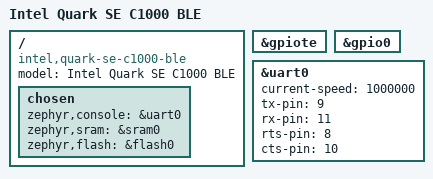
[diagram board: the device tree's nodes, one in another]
/*
 * Copyright (c) 2017 Linaro Limited
 *
 * SPDX-License-Identifier: Apache-2.0
 */

/dts-v1/;
#include <nordic/nrf51822_qfaa.dtsi>

/ {
	model = "Intel Quark SE C1000 BLE";
	compatible = "intel,quark-se-c1000-ble", "nordic,nrf51822-qfaa",
		     "nordic,nrf51822";

	chosen {
		zephyr,console = &uart0;
		zephyr,sram = &sram0;
		zephyr,flash = &flash0;
	};
};

&gpiote {
	status ="ok";
};

&gpio0 {
	status ="ok";
};

&uart0 {
	status = "ok";
	current-speed = <1000000>;
	tx-pin = <9>;
	rx-pin = <11>;
	rts-pin = <8>;
	cts-pin = <10>;
};
